AUTOSAR XML (schema 4-2-2)
package /ASW_COM_Package
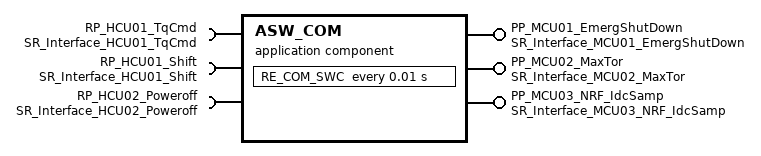
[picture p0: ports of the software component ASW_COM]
  application sw component type ASW_COM
    provide port PP_MCU01_EmergShutDown: provided-interface=SR_Interface_MCU01_EmergShutDown
    provide port PP_MCU02_MaxTor: provided-interface=SR_Interface_MCU02_MaxTor
    provide port PP_MCU03_NRF_IdcSamp: provided-interface=SR_Interface_MCU03_NRF_IdcSamp
    require port RP_HCU01_TqCmd: required-interface=SR_Interface_HCU01_TqCmd
    require port RP_HCU01_Shift: required-interface=SR_Interface_HCU01_Shift
    require port RP_HCU02_Poweroff: nonqueued-receiver-com-spec{data-element=DE_Poweroff, alive-timeout=0.3, init-value=0}, required-interface=SR_Interface_HCU02_Poweroff
    behavior IB_ASW_COM
      timing event TE_RE_COM_SWC_10ms: start-on-event=RE_COM_SWC, period=0.01
      runnable RE_COM_SWC
        data-read-access:
          access R_HCU01_TqCmd: accessed-variable=RP_HCU01_TqCmd.DE_TqCmd
          access R_HCU01_Shift: accessed-variable=RP_HCU01_Shift.DE_Shift
          access R_HCU02_Poweroff: accessed-variable=RP_HCU02_Poweroff.DE_Poweroff
        data-write-access:
          access P_MCU01_EmergShutDown: accessed-variable=PP_MCU01_EmergShutDown.DE_EmergShutDown
          access P_MCU02_MaxTor: accessed-variable=PP_MCU02_MaxTor.DE_MaxTor
          access P_MCU03_NRF_IdcSamp: accessed-variable=PP_MCU03_NRF_IdcSamp.DE_NRF_IdcSamp
package /COM_Interface
  6 x sender receiver interface:
    SR_Interface_MCU01_EmergShutDown
      data DE_EmergShutDown: type=dt_boolean
    SR_Interface_MCU02_MaxTor
      data DE_MaxTor: type=dt_uint16
    SR_Interface_MCU03_NRF_IdcSamp
      data DE_NRF_IdcSamp: type=dt_uint16
    SR_Interface_HCU01_TqCmd
      data DE_TqCmd: type=dt_sint16
    SR_Interface_HCU01_Shift
      data DE_Shift: type=dt_uint8
    SR_Interface_HCU02_Poweroff
      data DE_Poweroff: type=dt_boolean
package /DataTypes
  4 x impl type, all with category=VALUE:
    dt_boolean: base-type=boolean
    dt_uint16: base-type=uint16
    dt_sint16: base-type=sint16
    dt_uint8: base-type=uint8
